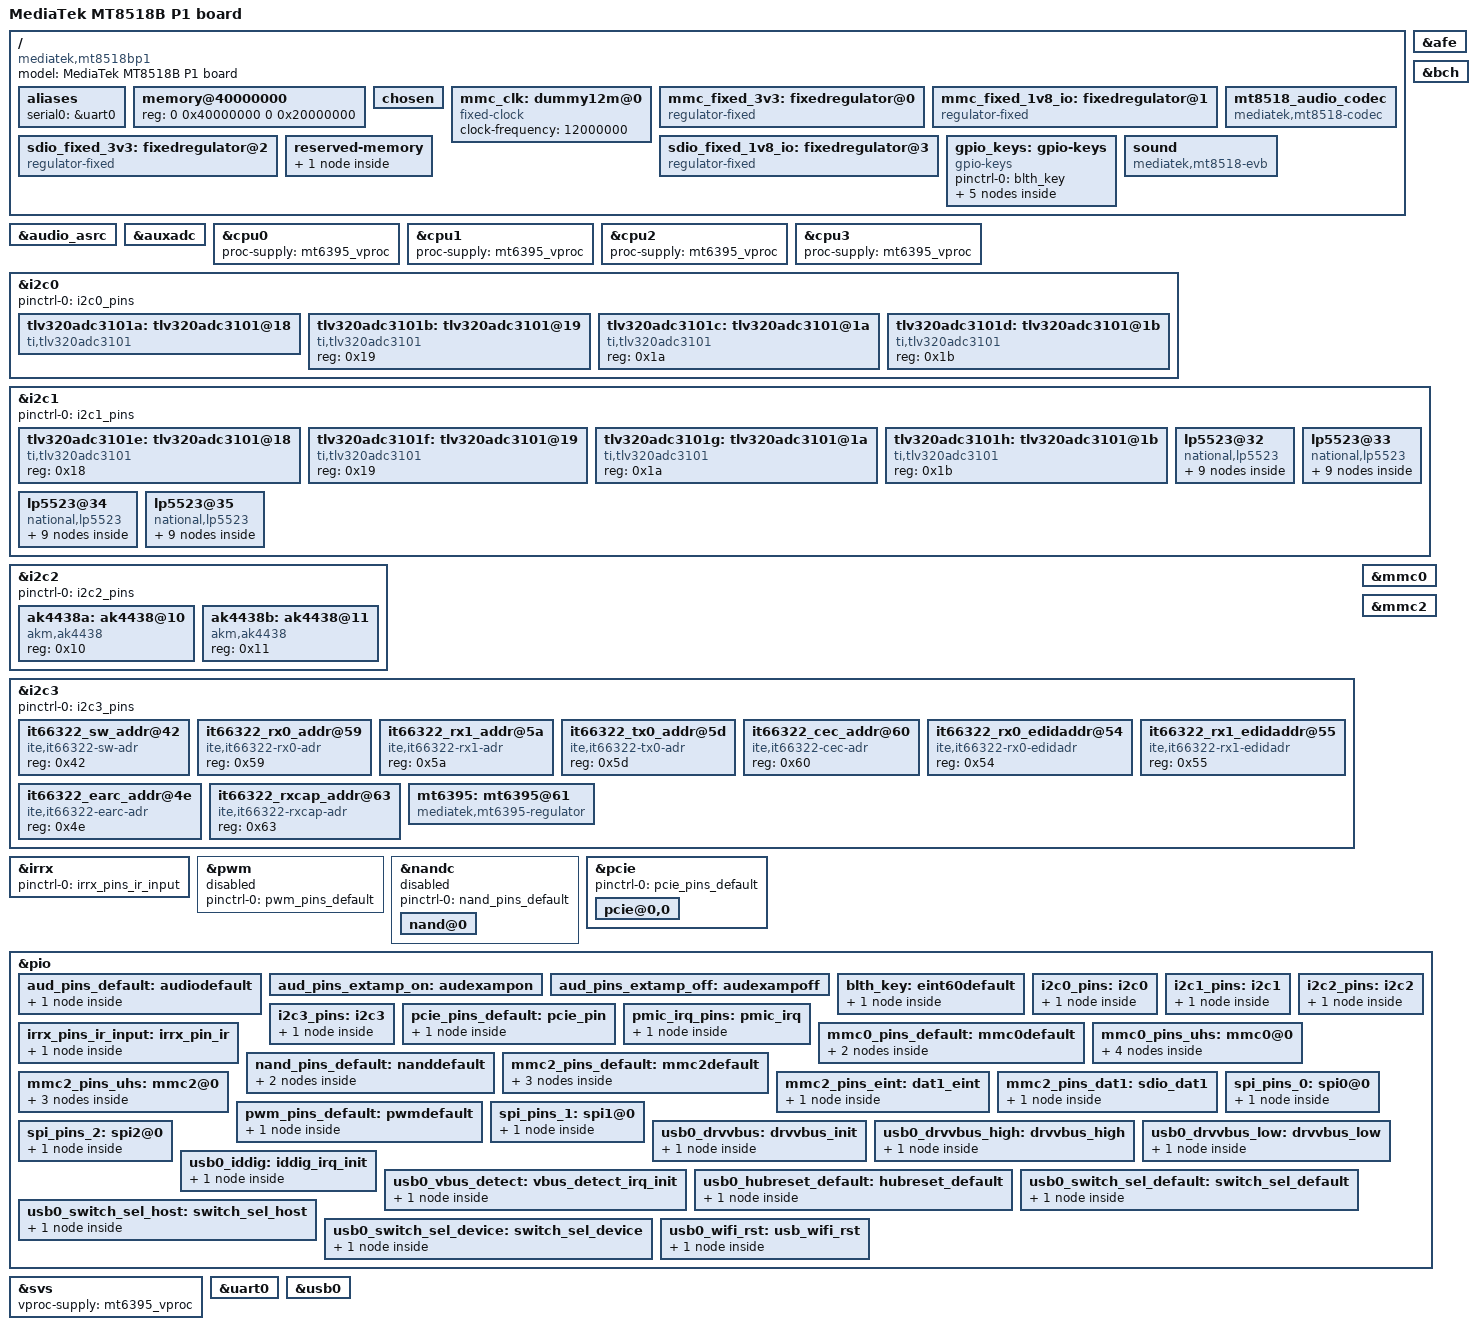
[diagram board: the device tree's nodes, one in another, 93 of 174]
/*
 * Copyright (c) 2018 MediaTek Inc.
 *
 * SPDX-License-Identifier: (GPL-2.0 OR MIT)
 */

/dts-v1/;
#include "mt8518b.dtsi"

/ {
	model = "MediaTek MT8518B P1 board";
	compatible = "mediatek,mt8518bp1", "mediatek,mt8518";

	aliases {
		serial0 = &uart0;
	};

	memory@40000000 {
		device_type = "memory";
		reg = <0 0x40000000 0 0x20000000>;
	};

	chosen {
		bootargs = "console=ttyS0,115200n1 root=/dev/mmcblk0p9 \
0x91ea22 earlycon=uart8250,mmio32,\
0x11005000 initcall_debug loglevel=8 \
androidboot.hardware=mt8518 \
firmware_class.path=/vendor/firmware";
	};

	mmc_clk: dummy12m@0 {
		compatible = "fixed-clock";
		clock-frequency = <12000000>;
		#clock-cells = <0>;
	};

	mmc_fixed_3v3: fixedregulator@0 {
		compatible = "regulator-fixed";
		regulator-name = "mmc_power";
		regulator-min-microvolt = <3300000>;
		regulator-max-microvolt = <3300000>;
		enable-active-high;
		regulator-always-on;
	};

	mmc_fixed_1v8_io: fixedregulator@1 {
		compatible = "regulator-fixed";
		regulator-name = "mmc_io";
		regulator-min-microvolt = <1800000>;
		regulator-max-microvolt = <1800000>;
		enable-active-high;
		regulator-always-on;
	};

	sdio_fixed_3v3: fixedregulator@2 {
			compatible = "regulator-fixed";
			regulator-name = "sdio_power";
			regulator-min-microvolt = <3300000>;
			regulator-max-microvolt = <3300000>;
			enable-active-high;
			regulator-always-on;
	};

	sdio_fixed_1v8_io: fixedregulator@3 {
			compatible = "regulator-fixed";
			regulator-name = "sdio_io";
			regulator-min-microvolt = <1800000>;
			regulator-max-microvolt = <1800000>;
			gpio = <&pio 55 0>;
			enable-active-high;
	};

	mt8518_audio_codec: mt8518_audio_codec {
		compatible = "mediatek,mt8518-codec";
		mediatek,afe-regmap = <&afe>;
		mediatek,apmixedsys-regmap = <&apmixedsys>;
		clocks = <&topckgen CLK_TOP_FAUD_INTBUS>;
		clock-names = "bus";
	};

	gpio_keys: gpio-keys {
		compatible = "gpio-keys";
		pinctrl-names = "default";
		pinctrl-0 = <&blth_key>;
		status = "okay";

		button@0 {
			debounce_interval = <50>;
			gpios = <&pio 57 1>;
			label = "volumeup";
			linux,input-type = <0x1>;
			linux,code = <115>;
		};

		button@1 {
			debounce_interval = <50>;
			gpios = <&pio 58 1>;
			label = "volumedown";
			linux,input-type = <0x1>;
			linux,code = <114>;
		};

		button@2 {
			debounce_interval = <50>;
			gpios = <&pio 61 1>;
			label = "bluetooth";
			linux,input-type = <0x1>;
			linux,code = <237>;
		};

		mute_button: button@3 {
			debounce_interval = <50>;
			gpios = <&pio 59 1>;
			label = "mute";
			linux,input-type = <0x1>;
			linux,code = <248>;
		};

		button@4 {
			debounce_interval = <50>;
			gpios = <&pio 62 1>;
			label = "switch";
			linux,input-type = <0x1>;
			linux,code = <31>;
		};

	};

	reserved-memory {
		mtee-reserved-memory {
			compatible = "mediatek,mt8518-mtee-reserved-memory";
			no-map;
			reg = <0 0x5FD00000 0 0x300000>;
		};
	};

	sound: sound {
		compatible = "mediatek,mt8518-evb";
		mediatek,platform = <&afe>;
		mediatek,etdm1-out-audio-codec-num = <2>;
		mediatek,etdm1-out-audio-codec0 = <&ak4438a>;
		mediatek,etdm1-out-audio-codec1 = <&ak4438b>;
		mediatek,etdm1-out-audio-codec0-prefix = "AK4438@10";
		mediatek,etdm1-out-audio-codec1-prefix = "AK4438@11";
		mediatek,etdm1-out-codec-dai-name0 = "ak4438-AIF";
		mediatek,etdm1-out-codec-dai-name1 = "ak4438-AIF";
		mediatek,etdm1-in-format = "dsp_a";
		mediatek,etdm1-in-lrck-width = <1>;
		mediatek,etdm1-in-audio-codec = <&tlv320adc3101a>;
		mediatek,etdm1-in-codec-dai-name = "tlv320adc3101-codec";
		mediatek,etdm1-in-fix-bit-width = <16>;
		mediatek,etdm1-in-fix-channels = <16>;
		mediatek,tlv320adc3101-codec-set-pll-clk-in-hw-params;
		mediatek,tlv320adc3101-codec-pll-id = <0>;
		mediatek,tlv320adc3101-codec-pll-src-id = <0>;
		mediatek,tlv320adc3101-codec-pll-clk-multiplier = <256>;
		mediatek,etdm2-in-format = "i2s";
		mediatek,etdm2-in-fix-bit-width = <32>;
		mediatek,int-adda-audio-codec=<&mt8518_audio_codec>;
		mediatek,int-adda-codec-dai-name="mt8518-codec-dai";
		mediatek,multi-in-fix-bit-width = <32>;
		pinctrl-names = "default", "extamp_on", "extamp_off";
		pinctrl-0 = <&aud_pins_default>;
		pinctrl-1 = <&aud_pins_extamp_on>;
		pinctrl-2 = <&aud_pins_extamp_off>;
		status = "okay";
	};
};

&afe {
	mediatek,dmic-iir-on;
	mediatek,etdm-clock-modes = <0 0>;
	mediatek,etdm-out-data-modes = <1 1>;
	mediatek,etdm-in-data-modes = <0 1>;
	mediatek,spdif-in-opt-mux = <0>;
	mediatek,spdif-in-arc-mux = <2>;
	mediatek,multi-in-clk-tuning-enabled;
	mediatek,multi-in-clk-tuning-period-ms = <1000>;
	mediatek,multi-in-clk-step-ppm = <1>;
	mediatek,multi-in-clk-step-interval-us = <200>;
	mediatek,spdif-in-clk-tuning-enabled;
	mediatek,spdif-in-clk-tuning-period-ms = <1000>;
	mediatek,spdif-in-clk-step-ppm = <1>;
	mediatek,spdif-in-clk-step-interval-us = <200>;
	mediatek,etdm1-out-clk-tuning-enabled;
	status = "okay";
};

&audio_asrc {
	status = "okay";
};

&auxadc {
	status = "okay";
};

&bch {
	status = "okay";
};

&cpu0 {
	proc-supply = <&mt6395_vproc>;
};

&cpu1 {
	proc-supply = <&mt6395_vproc>;
};

&cpu2 {
	proc-supply = <&mt6395_vproc>;
};

&cpu3 {
	proc-supply = <&mt6395_vproc>;
};

&i2c0 {
	pinctrl-names = "default";
	pinctrl-0 = <&i2c0_pins>;
	status = "okay";

	tlv320adc3101a: tlv320adc3101@18 {
		compatible = "ti,tlv320adc3101";
		reg = <0x18>;
		rst-gpio = <&pio 19 0>;
		adc-pos = <0>;
		dmic-en =<0>;
		diff-single = <0>;
		left-adc-sel = <2>;
		right-adc-sel = <2>;
	};

	tlv320adc3101b: tlv320adc3101@19 {
		compatible = "ti,tlv320adc3101";
		reg = <0x19>;
	};

	tlv320adc3101c: tlv320adc3101@1a {
		compatible = "ti,tlv320adc3101";
		reg = <0x1a>;
	};

	tlv320adc3101d: tlv320adc3101@1b {
		compatible = "ti,tlv320adc3101";
		reg = <0x1b>;
	};

};

&i2c1 {
	pinctrl-names = "default";
	pinctrl-0 = <&i2c1_pins>;
	status = "okay";

	tlv320adc3101e: tlv320adc3101@18 {
		compatible = "ti,tlv320adc3101";
		reg = <0x18>;
	};

	tlv320adc3101f: tlv320adc3101@19 {
		compatible = "ti,tlv320adc3101";
		reg = <0x19>;
	};

	tlv320adc3101g: tlv320adc3101@1a {
		compatible = "ti,tlv320adc3101";
		reg = <0x1a>;
	};

	tlv320adc3101h: tlv320adc3101@1b {
		compatible = "ti,tlv320adc3101";
		reg = <0x1b>;
	};

	lp5523@32{
	compatible = "national,lp5523";
	reg = <0x32>;
	enable-gpio = <&pio 25 0>;
	clock-mode = /bits/ 8 <1>;

	chan0 {
		chan-name = "d1";
		led-cur = /bits/ 8 <0x20>;
		max-cur = /bits/ 8 <0xff>;
	};

	chan1 {
		chan-name = "d2";
		led-cur = /bits/ 8 <0x20>;
		max-cur = /bits/ 8 <0xff>;
	};

	chan2 {
		chan-name = "d3";
		led-cur = /bits/ 8 <0x20>;
		max-cur = /bits/ 8 <0xff>;
	};

	chan3 {
		chan-name = "d4";
		led-cur = /bits/ 8 <0x20>;
		max-cur = /bits/ 8 <0xff>;
	};

	chan4 {
		chan-name = "d5";
		led-cur = /bits/ 8 <0x20>;
		max-cur = /bits/ 8 <0xff>;
	};

	chan5 {
		chan-name = "d6";
		led-cur = /bits/ 8 <0x20>;
		max-cur = /bits/ 8 <0xff>;
	};

	chan6 {
		chan-name = "d7";
		led-cur = /bits/ 8 <0x20>;
		max-cur = /bits/ 8 <0xff>;
	};

	chan7 {
		chan-name = "d8";
		led-cur = /bits/ 8 <0x20>;
		max-cur = /bits/ 8 <0xff>;
	};

	chan8 {
		chan-name = "d9";
		led-cur = /bits/ 8 <0x20>;
		max-cur = /bits/ 8 <0xff>;
		};
	};
	lp5523@33{
	compatible = "national,lp5523";
	reg = <0x33>;
	enable-gpio = <&pio 25 0>;
	clock-mode = /bits/ 8 <1>;

	chan0 {
		chan-name = "d1_1";
		led-cur = /bits/ 8 <0x20>;
		max-cur = /bits/ 8 <0xff>;
	};

	chan1 {
		chan-name = "d1_2";
		led-cur = /bits/ 8 <0x20>;
		max-cur = /bits/ 8 <0xff>;
	};

	chan2 {
		chan-name = "d1_3";
		led-cur = /bits/ 8 <0x20>;
		max-cur = /bits/ 8 <0xff>;
	};
	chan3 {
		chan-name = "d1_4";
		led-cur = /bits/ 8 <0x20>;
		max-cur = /bits/ 8 <0xff>;
	};

	chan4 {
		chan-name = "d1_5";
		led-cur = /bits/ 8 <0x20>;
		max-cur = /bits/ 8 <0xff>;
	};

	chan5 {
		chan-name = "d1_6";
		led-cur = /bits/ 8 <0x20>;
		max-cur = /bits/ 8 <0xff>;
	};

	chan6 {
		chan-name = "d1_7";
		led-cur = /bits/ 8 <0x20>;
		max-cur = /bits/ 8 <0xff>;
	};

	chan7 {
		chan-name = "d1_8";
		led-cur = /bits/ 8 <0x20>;
		max-cur = /bits/ 8 <0xff>;
	};

	chan8 {
		chan-name = "d1_9";
		led-cur = /bits/ 8 <0x20>;
		max-cur = /bits/ 8 <0xff>;
		};
	};
	lp5523@34{
	compatible = "national,lp5523";
	reg = <0x34>;
	enable-gpio = <&pio 25 0>;
	clock-mode = /bits/ 8 <1>;

	chan0 {
		chan-name = "d2_1";
		led-cur = /bits/ 8 <0x20>;
		max-cur = /bits/ 8 <0xff>;
	};

	chan1 {
		chan-name = "d2_2";
		led-cur = /bits/ 8 <0x20>;
		max-cur = /bits/ 8 <0xff>;
	};

	chan2 {
		chan-name = "d2_3";
		led-cur = /bits/ 8 <0x20>;
		max-cur = /bits/ 8 <0xff>;
	};

	chan3 {
		chan-name = "d2_4";
		led-cur = /bits/ 8 <0x20>;
		max-cur = /bits/ 8 <0xff>;
	};

	chan4 {
		chan-name = "d2_5";
		led-cur = /bits/ 8 <0x20>;
		max-cur = /bits/ 8 <0xff>;
	};

	chan5 {
		chan-name = "d2_6";
		led-cur = /bits/ 8 <0x20>;
		max-cur = /bits/ 8 <0xff>;
	};

	chan6 {
		chan-name = "d2_7";
		led-cur = /bits/ 8 <0x20>;
		max-cur = /bits/ 8 <0xff>;
	};

	chan7 {
		chan-name = "d2_8";
		led-cur = /bits/ 8 <0x20>;
		max-cur = /bits/ 8 <0xff>;
	};

	chan8 {
		chan-name = "d2_9";
		led-cur = /bits/ 8 <0x20>;
		max-cur = /bits/ 8 <0xff>;
		};
	};
	lp5523@35{
	compatible = "national,lp5523";
	reg = <0x35>;
	enable-gpio = <&pio 25 0>;
	clock-mode = /bits/ 8 <1>;

	chan0 {
		chan-name = "d3_1";
		led-cur = /bits/ 8 <0x20>;
		max-cur = /bits/ 8 <0xff>;
	};

	chan1 {
		chan-name = "d3_2";
		led-cur = /bits/ 8 <0x20>;
		max-cur = /bits/ 8 <0xff>;
	};

	chan2 {
		chan-name = "d3_3";
		led-cur = /bits/ 8 <0x20>;
		max-cur = /bits/ 8 <0xff>;
	};

	chan3 {
		chan-name = "d3_4";
		led-cur = /bits/ 8 <0x20>;
		max-cur = /bits/ 8 <0xff>;
	};

	chan4 {
		chan-name = "d3_5";
		led-cur = /bits/ 8 <0x20>;
		max-cur = /bits/ 8 <0xff>;
	};

	chan5 {
		chan-name = "d3_6";
		led-cur = /bits/ 8 <0x20>;
		max-cur = /bits/ 8 <0xff>;
	};

	chan6 {
		chan-name = "d3_7";
		led-cur = /bits/ 8 <0x20>;
		max-cur = /bits/ 8 <0xff>;
	};

	chan7 {
		chan-name = "d3_8";
		led-cur = /bits/ 8 <0x20>;
		max-cur = /bits/ 8 <0xff>;
	};

	chan8 {
		chan-name = "d3_9";
		led-cur = /bits/ 8 <0x20>;
		max-cur = /bits/ 8 <0xff>;
		};
	};
};

&i2c2 {
	pinctrl-names = "default";
	pinctrl-0 = <&i2c2_pins>;
	status = "okay";

	ak4438a: ak4438@10 {
		compatible = "akm,ak4438";
		reg = <0x10>;
	};

	ak4438b: ak4438@11 {
		compatible = "akm,ak4438";
		reg = <0x11>;
	};
};

&i2c3 {
	pinctrl-names = "default";
	pinctrl-0 = <&i2c3_pins>;
	status = "okay";

#if 0
	/*for it6620*/
	it66121_addr@4c {
		compatible = "ite,it66121-i2c";
		reg = <0x4c>;
	};
	it6620_basic_addr@4e {
		compatible = "ite,it6620-basic-i2c";
		reg = <0x4e>;
	};
	it6620_cec_addr@65 {
		compatible = "ite,it6620-cec-i2c";
		reg = <0x65>;
	};
	it6620_cap_addr@63 {
		compatible = "ite,it6620-cap-i2c";
		reg = <0x63>;
	};
#else
	/*for it66322*/
	it66322_sw_addr@42 {
		compatible = "ite,it66322-sw-adr";
		reg = <0x42>;
	};
	it66322_rx0_addr@59 {
		compatible = "ite,it66322-rx0-adr";
		reg = <0x59>;
	};
	it66322_rx1_addr@5a {
		compatible = "ite,it66322-rx1-adr";
		reg = <0x5a>;
	};
	it66322_tx0_addr@5d {
		compatible = "ite,it66322-tx0-adr";
		reg = <0x5d>;
	};
	it66322_cec_addr@60 {
		compatible = "ite,it66322-cec-adr";
		reg = <0x60>;
	};
	it66322_rx0_edidaddr@54 {
		compatible = "ite,it66322-rx0-edidadr";
		reg = <0x54>;
	};
	it66322_rx1_edidaddr@55 {
		compatible = "ite,it66322-rx1-edidadr";
		reg = <0x55>;
	};
	it66322_earc_addr@4e {
		compatible = "ite,it66322-earc-adr";
		reg = <0x4e>;
	};
	it66322_rxcap_addr@63 {
		compatible = "ite,it66322-rxcap-adr";
		reg = <0x63>;
	};
#endif

	mt6395: mt6395@61 {
		compatible = "mediatek,mt6395-regulator";
		pinctrl-names = "default";
		pinctrl-0 = <&pmic_irq_pins>;
		mt6395,irq-gpios = <&pio 27 0x0>;
		reg = <0x61>;
		status = "okay";
	};
};

&irrx {
	pinctrl-names = "default";
	pinctrl-0 = <&irrx_pins_ir_input>;
	status = "okay";
};

&pwm {
	pinctrl-names = "default";
	pinctrl-0 = <&pwm_pins_default>;
	status = "disabled";
};

&mmc0 {
	pinctrl-names = "default", "state_uhs";
	pinctrl-0 = <&mmc0_pins_default>;
	pinctrl-1 = <&mmc0_pins_uhs>;
	status = "okay";
	bus-width = <8>;
	max-frequency = <200000000>;
	cap-mmc-highspeed;
	cap-mmc-hw-reset;
	mmc-hs200-1_8v;
	mmc-hs400-1_8v;
	hs400-ds-delay = <0x1201d>;
	r_smpl = <0>;
	vmmc-supply = <&mmc_fixed_3v3>;
	vqmmc-supply = <&mmc_fixed_1v8_io>;
	no-sdio;
	no-sd;
	non-removable;
};

&mmc2 {
	status = "okay";
	pinctrl-names = "default", "state_uhs", "state_eint", "state_dat1";
	pinctrl-0 = <&mmc2_pins_default>;
	pinctrl-1 = <&mmc2_pins_uhs>;
	pinctrl-2 = <&mmc2_pins_eint>;
	pinctrl-3 = <&mmc2_pins_dat1>;
	eint-gpios = <&pio 32 0>;
	bus-width = <4>;
	max-frequency = <200000000>;
	cap-sd-highspeed;
	/*sd-uhs-ddr208;*/
	drv-type = <2>;
	sd-uhs-sdr104;
	sd-uhs-sdr50;
	keep-power-in-suspend;
	enable-sdio-wakeup;
	cap-sdio-irq;
	hs400-ds-delay = <0x1401B>;
	no-sd;
	no-mmc;
	non-removable;
	vmmc-supply = <&sdio_fixed_3v3>;
	vqmmc-supply = <&sdio_fixed_1v8_io>;
};

&nandc {
	pinctrl-names = "default";
	pinctrl-0 = <&nand_pins_default>;
	status = "disabled";
	nand@0 {
		reg = <0>;
		nand-on-flash-bbt;
		nand-ecc-mode = "hw";
	};
};

&pcie {
	pinctrl-names = "default";
	pinctrl-0 = <&pcie_pins_default>;
	pcie@0,0 {
		speed =  <1>;
		rst-gpio = <&pio 116 0>;
		rst-2g-gpio = <&pio 114 0>;
		rst-5g-gpio = <&pio 115 0>;
		status = "okay";
	};
};

&pio {
	pinctrl-names = "default";

	aud_pins_default: audiodefault {
		pins_cmd_dat {
			pinmux = <MT8518_PIN_47_EINT11__FUNC_SPLIN_BCK>,
				<MT8518_PIN_48_EINT12__FUNC_SPLIN_LRCK>,
				<MT8518_PIN_49_EINT13__FUNC_SPLIN_D0>,
				<MT8518_PIN_50_EINT14__FUNC_SPLIN_D1>,
				<MT8518_PIN_51_EINT15__FUNC_SPLIN_D2>,
				<MT8518_PIN_63_I2SO_MCLK__FUNC_TDMO_MCLK>,
				<MT8518_PIN_64_I2SO_BCK__FUNC_TDMO_BCK>,
				<MT8518_PIN_65_I2SO_LRCK__FUNC_TDMO_LRCK>,
				<MT8518_PIN_66_I2SO_D0__FUNC_TDMO_DO>,
				<MT8518_PIN_67_I2SO_D1__FUNC_TDMO_DO1>,
				<MT8518_PIN_68_I2SO_D2__FUNC_TDMO_DO2>,
				<MT8518_PIN_69_I2SO_D3__FUNC_TDMO_DO3>,
				<MT8518_PIN_70_SPDIF_IN0__FUNC_SPDIF_IN_0>,
				<MT8518_PIN_71_DMIC_CLK0__FUNC_DMIC_CLK0>,
				<MT8518_PIN_72_DMIC_CLK1__FUNC_DMIC_CLK1>,
				<MT8518_PIN_73_DMIC_DAT0__FUNC_DMIC_DAT0>,
				<MT8518_PIN_74_DMIC_DAT1__FUNC_DMIC_DAT1>,
				<MT8518_PIN_75_DMIC_DAT2__FUNC_DMIC_DAT2>,
				<MT8518_PIN_76_DMIC_DAT3__FUNC_DMIC_DAT3>,
				<MT8518_PIN_77_TDM_MCLK__FUNC_TDMIN_MCLK>,
				<MT8518_PIN_78_TDM_BCK__FUNC_TDMIN_BCK>,
				<MT8518_PIN_79_TDM_LRCK__FUNC_TDMIN_LRCK>,
				<MT8518_PIN_80_TDM_DI__FUNC_TDMIN_DI>,
				<MT8518_PIN_81_I2SIN_D0__FUNC_I2SIN_D0>,
				<MT8518_PIN_84_I2SIN_D3__FUNC_SPLIN_D3>,
				<MT8518_PIN_85_I2SIN_MCLK__FUNC_I2SIN_MCLKA>,
				<MT8518_PIN_86_I2SIN_BCK__FUNC_I2SIN_BCKA>,
				<MT8518_PIN_87_I2SIN_LRCK__FUNC_I2SIN_LRCKA>,
				<MT8518_PIN_92_SPI2_CS__FUNC_TDMO_DO4>,
				<MT8518_PIN_93_SPI2_CK__FUNC_TDMO_DO5>,
				<MT8518_PIN_94_SPI2_MI0__FUNC_TDMO_DO6>,
				<MT8518_PIN_95_SPI2_MI1__FUNC_TDMO_DO7>,
				<MT8518_PIN_103_RTC32K_DSP__FUNC_SPDIF_IN_2>;
		};
	};

	aud_pins_extamp_on: audexampon {
	};

	aud_pins_extamp_off: audexampoff {
	};

	blth_key: eint60default {
		pins_cmd_dat {
			pinmux = <MT8518_PIN_57_EINT16__FUNC_GPIO57>,
				<MT8518_PIN_58_EINT17__FUNC_GPIO58>,
				<MT8518_PIN_59_EINT18__FUNC_GPIO59>,
				<MT8518_PIN_61_EINT20__FUNC_GPIO61>,
				<MT8518_PIN_62_EINT21__FUNC_GPIO62>;
			slew-rate = <0>;
			bias-pull-up = <MTK_PUPD_SET_R1R0_01>;
			input-enable;
		};
	};

	i2c0_pins: i2c0 {
		pins_bus {
			pinmux = <MT8518_PIN_110_SDA0__FUNC_SDA0_0>,
				 <MT8518_PIN_111_SCL0__FUNC_SCL0_0>;
			bias-disable;
		};
	};

	i2c1_pins: i2c1 {
		pins_bus {
			pinmux = <MT8518_PIN_108_SDA1__FUNC_SDA1_0>,
				 <MT8518_PIN_109_SCL1__FUNC_SCL1_0>;
			bias-disable;
		};
	};

	i2c2_pins: i2c2 {
		pins_bus {
			pinmux = <MT8518_PIN_112_SDA2__FUNC_SDA2_0>,
				 <MT8518_PIN_113_SCL2__FUNC_SCL2_0>;
			bias-disable;
		};
	};

	i2c3_pins: i2c3 {
		pins_bus {
			pinmux = <MT8518_PIN_21_SDA3__FUNC_SDA3_0>,
				 <MT8518_PIN_22_SCL3__FUNC_SCL3_0>;
			bias-disable;
		};
	};

	pcie_pins_default: pcie_pin {
		pins_pcie {
			pinmux = <MT8518_PIN_116_MSDC1_DAT0__FUNC_GPIO116>,
				<MT8518_PIN_119_MSDC1_DAT3__FUNC_GPIO119>,
				<MT8518_PIN_60_EINT19__FUNC_PCIE_CLKREQ>;
			bias-disable;
		};
	};

	irrx_pins_ir_input: irrx_pin_ir {
		pins_cmd_dat {
			pinmux = <MT8518_PIN_56_IR__FUNC_IR>;
			bias-disable;
		};
	};

	pmic_irq_pins: pmic_irq {
		pins_bus {
			pinmux = <MT8518_PIN_27_PWRAP_INT__FUNC_GPIO27>;
			bias-pull-up = <MTK_PUPD_SET_R1R0_01>;
		};
	};

	mmc0_pins_default: mmc0default {
		pins_cmd_dat {
			pinmux = <MT8518_PIN_13_MSDC0_DAT0__FUNC_MSDC0_DAT0>,
				<MT8518_PIN_12_MSDC0_DAT1__FUNC_MSDC0_DAT1>,
				<MT8518_PIN_11_MSDC0_DAT2__FUNC_MSDC0_DAT2>,
				<MT8518_PIN_10_MSDC0_DAT3__FUNC_MSDC0_DAT3>,
				<MT8518_PIN_6_MSDC0_DAT4__FUNC_MSDC0_DAT4>,
				<MT8518_PIN_5_MSDC0_DAT5__FUNC_MSDC0_DAT5>,
				<MT8518_PIN_4_MSDC0_DAT6__FUNC_MSDC0_DAT6>,
				<MT8518_PIN_3_MSDC0_DAT7__FUNC_MSDC0_DAT7>,
				<MT8518_PIN_8_MSDC0_CMD__FUNC_MSDC0_CMD>;
			input-enable;
			bias-pull-up;
		};

		pins_clk {
			pinmux = <MT8518_PIN_9_MSDC0_CLK__FUNC_MSDC0_CLK>;
			bias-pull-down;
		};
	};

	mmc0_pins_uhs: mmc0@0{
		pins_cmd_dat {
			pinmux = <MT8518_PIN_13_MSDC0_DAT0__FUNC_MSDC0_DAT0>,
				 <MT8518_PIN_12_MSDC0_DAT1__FUNC_MSDC0_DAT1>,
				 <MT8518_PIN_11_MSDC0_DAT2__FUNC_MSDC0_DAT2>,
				 <MT8518_PIN_10_MSDC0_DAT3__FUNC_MSDC0_DAT3>,
				 <MT8518_PIN_6_MSDC0_DAT4__FUNC_MSDC0_DAT4>,
				 <MT8518_PIN_5_MSDC0_DAT5__FUNC_MSDC0_DAT5>,
				 <MT8518_PIN_4_MSDC0_DAT6__FUNC_MSDC0_DAT6>,
				 <MT8518_PIN_3_MSDC0_DAT7__FUNC_MSDC0_DAT7>,
				 <MT8518_PIN_8_MSDC0_CMD__FUNC_MSDC0_CMD>;
			input-enable;
			drive-strength = <MTK_DRIVE_6mA>;
			bias-pull-up;
		};

		pins_clk {
			pinmux = <MT8518_PIN_9_MSDC0_CLK__FUNC_MSDC0_CLK>;
			drive-strength = <MTK_DRIVE_8mA>;
			bias-pull-down;
		};

		pins_ds {
			pinmux = <MT8518_PIN_2_NFI_NRNB__FUNC_MSDC0_DS>;
			bias-pull-down = <MTK_PUPD_SET_R1R0_10>;
		};

		pins_rst {
			pinmux = <MT8518_PIN_7_MSDC0_RSTB__FUNC_MSDC0_RSTB>;
			bias-pull-up;
		};
	};

	nand_pins_default: nanddefault {
		pins_dat {
			pinmux = <MT8518_PIN_3_MSDC0_DAT7__FUNC_NLD7>,
				 <MT8518_PIN_4_MSDC0_DAT6__FUNC_NLD6>,
				 <MT8518_PIN_5_MSDC0_DAT5__FUNC_NLD4>,
				 <MT8518_PIN_6_MSDC0_DAT4__FUNC_NLD3>,
				 <MT8518_PIN_7_MSDC0_RSTB__FUNC_NLD0>,
				 <MT8518_PIN_10_MSDC0_DAT3__FUNC_NLD1>,
				 <MT8518_PIN_11_MSDC0_DAT2__FUNC_NLD5>,
				 <MT8518_PIN_13_MSDC0_DAT0__FUNC_NLD2>;
			input-enable;
			bias-pull-up;
		};

		pins_cmd {
			pinmux = <MT8518_PIN_0_NFI_NCEB0__FUNC_NCEB0>,
				 <MT8518_PIN_1_NFI_NREB__FUNC_NREB>,
				 <MT8518_PIN_2_NFI_NRNB__FUNC_NRNB>,
				 <MT8518_PIN_8_MSDC0_CMD__FUNC_NALE>,
				 <MT8518_PIN_9_MSDC0_CLK__FUNC_NWEB>,
				 <MT8518_PIN_12_MSDC0_DAT1__FUNC_NCLE>;
			bias-pull-up;
		};
	};

	mmc2_pins_default: mmc2default {
		pins_cmd_dat {
			pinmux = <MT8518_PIN_29_MSDC2_CMD__FUNC_MSDC2_CMD>,
			       <MT8518_PIN_31_MSDC2_DAT0__FUNC_MSDC2_DAT0>,
			       <MT8518_PIN_32_MSDC2_DAT1__FUNC_MSDC2_DAT1>,
			       <MT8518_PIN_33_MSDC2_DAT2__FUNC_MSDC2_DAT2>,
			       <MT8518_PIN_34_MSDC2_DAT3__FUNC_MSDC2_DAT3>;
			input-enable;
			bias-pull-up = <MTK_PUPD_SET_R1R0_01>;
		};

		pins_clk {
			pinmux = <MT8518_PIN_30_MSDC2_CLK__FUNC_MSDC2_CLK>;
			bias-pull-down = <MTK_PUPD_SET_R1R0_10>;
		};

		pins_wifi_clk {
			pinmux = <MT8518_PIN_23_PWRAP_SPI_CLK__FUNC_GPIO23>,
			       <MT8518_PIN_54_URTS1__FUNC_GPIO54>;
			input-enable;
			bias-disable;
		};
	};

	mmc2_pins_uhs: mmc2@0{
		pins_cmd_dat {
			pinmux = <MT8518_PIN_29_MSDC2_CMD__FUNC_MSDC2_CMD>,
			       <MT8518_PIN_31_MSDC2_DAT0__FUNC_MSDC2_DAT0>,
			       <MT8518_PIN_32_MSDC2_DAT1__FUNC_MSDC2_DAT1>,
			       <MT8518_PIN_33_MSDC2_DAT2__FUNC_MSDC2_DAT2>,
			       <MT8518_PIN_34_MSDC2_DAT3__FUNC_MSDC2_DAT3>;
			input-enable;
			drive-strength = <MTK_DRIVE_4mA>;
			bias-pull-up = <MTK_PUPD_SET_R1R0_01>;
		};

		pins_clk {
			pinmux = <MT8518_PIN_30_MSDC2_CLK__FUNC_MSDC2_CLK>;
			drive-strength = <MTK_DRIVE_4mA>;
			bias-pull-down = <MTK_PUPD_SET_R1R0_10>;
		};

		pins_ds {
			pinmux = <MT8518_PIN_35_MSDC2_DS__FUNC_MSDC2_DS>;
			drive-strength = <MTK_DRIVE_4mA>;
			bias-pull-down = <MTK_PUPD_SET_R1R0_10>;
		};
	};

	mmc2_pins_eint: dat1_eint {
		pins_dat1 {
			pinmux = <MT8518_PIN_32_MSDC2_DAT1__FUNC_GPIO32>;
			output-high;
		};
	};

	mmc2_pins_dat1: sdio_dat1 {
		pins_dat1 {
			pinmux = <MT8518_PIN_32_MSDC2_DAT1__FUNC_MSDC2_DAT1>;
			input-enable;
			drive-strength = <MTK_DRIVE_4mA>;
			bias-pull-up = <MTK_PUPD_SET_R1R0_01>;
		};
	};

	pwm_pins_default: pwmdefault {
		pins_cmd_dat {
			pinmux = <MT8518_PIN_88_SPI1_CS__FUNC_PWM_A>,
				 <MT8518_PIN_89_SPI1_CK__FUNC_PWM_B>,
				 <MT8518_PIN_90_SPI1_MI__FUNC_PWM_C>;
		};
	};

	spi_pins_0: spi0@0 {
		pins_spi {
			pinmux = <MT8518_PIN_29_MSDC2_CMD__FUNC_SPI0_CSB>,
				<MT8518_PIN_30_MSDC2_CLK__FUNC_SPI0_CLK>,
				<MT8518_PIN_31_MSDC2_DAT0__FUNC_SPI0_MI>,
				<MT8518_PIN_32_MSDC2_DAT1__FUNC_SPI0_MO>;
			bias-disable;
			};
	};

	spi_pins_1: spi1@0 {
		pins_spi {
			pinmux = <MT8518_PIN_92_SPI2_CS__FUNC_SPI2_CSB>,
				<MT8518_PIN_93_SPI2_CK__FUNC_SPI2_CLK>,
				<MT8518_PIN_94_SPI2_MI0__FUNC_SPI2_MI0>,
				<MT8518_PIN_95_SPI2_MI1__FUNC_SPI2_MI1>,
				<MT8518_PIN_96_SPI2_MI2__FUNC_SPI2_MI2>,
				<MT8518_PIN_97_SPI2_MI3__FUNC_SPI2_MI3>;
			bias-disable;
		};
	};

	spi_pins_2: spi2@0 {
		pins_spi {
			pinmux = <MT8518_PIN_88_SPI1_CS__FUNC_SPI1_CSB>,
				<MT8518_PIN_89_SPI1_CK__FUNC_SPI1_CLK>,
				<MT8518_PIN_90_SPI1_MI__FUNC_SPI1_MI>,
				<MT8518_PIN_91_SPI1_MO__FUNC_SPI1_MO>;
			bias-disable;
		};
	};

	/* USB GPIO start */
	usb0_drvvbus: drvvbus_init {
		pins_cmd_dat {
			pinmux = <MT8518_PIN_57_EINT16__FUNC_GPIO57>;
			output-low;
		};
	};

	usb0_drvvbus_high: drvvbus_high {
		pins_cmd_dat {
			pinmux = <MT8518_PIN_57_EINT16__FUNC_GPIO57>;
			output-high;
		};
	};

	usb0_drvvbus_low: drvvbus_low {
		pins_cmd_dat {
			pinmux = <MT8518_PIN_57_EINT16__FUNC_GPIO57>;
			output-low;
		};
	};

	usb0_iddig: iddig_irq_init {
		pins_cmd_dat {
			pinmux = <MT8518_PIN_118_MSDC1_DAT2__FUNC_GPIO118>;
			bias-pull-up;
		};
	};

	usb0_vbus_detect: vbus_detect_irq_init {
		pins_cmd_dat {
			pinmux = <MT8518_PIN_60_EINT19__FUNC_GPIO60>;
			bias-disable;
		};
	};

	usb0_hubreset_default: hubreset_default {
		pins_cmd_dat {
			pinmux = <MT8518_PIN_91_SPI1_MO__FUNC_GPIO91>;
			output-high;
		};
	};

	usb0_switch_sel_default: switch_sel_default {
		pins_cmd_dat {
			pinmux = <MT8518_PIN_117_MSDC1_DAT1__FUNC_GPIO117>;
			output-low;
		};
	};

	usb0_switch_sel_host: switch_sel_host {
		pins_cmd_dat {
			pinmux = <MT8518_PIN_117_MSDC1_DAT1__FUNC_GPIO117>;
			output-low;
		};
	};

	usb0_switch_sel_device: switch_sel_device {
		pins_cmd_dat {
			pinmux = <MT8518_PIN_117_MSDC1_DAT1__FUNC_GPIO117>;
			output-high;
		};
	};

	usb0_wifi_rst: usb_wifi_rst {
		pins_cmd_dat {
			pinmux = <MT8518_PIN_115_MSDC1_CLK__FUNC_GPIO115>;
			output-low;
		};
	};
	/* USB GPIO end */
};

&svs {
	vproc-supply = <&mt6395_vproc>;
};

&uart0 {
	status = "okay";
};

&usb0 {
	interrupts-extended = <&sysirq GIC_SPI 72 IRQ_TYPE_LEVEL_LOW>;
	pinctrl-names = "iddig_irq_init",
			"drvvbus_init",
			"drvvbus_low",
			"drvvbus_high",
			"vbus_detect_irq_init",
			"hubreset_default",
			"switch_sel_default",
			"switch_sel_host",
			"switch_sel_device",
			"wifi_rst";
	pinctrl-0 = <&usb0_iddig>;
	pinctrl-1 = <&usb0_drvvbus>;
	pinctrl-2 = <&usb0_drvvbus_low>;
	pinctrl-3 = <&usb0_drvvbus_high>;
	pinctrl-4 = <&usb0_vbus_detect>;
	pinctrl-5 = <&usb0_hubreset_default>;
	pinctrl-6 = <&usb0_switch_sel_default>;
	pinctrl-7 = <&usb0_switch_sel_host>;
	pinctrl-8 = <&usb0_switch_sel_device>;
	status = "okay";
	sw_default_mode = <2>;
	hubreset_exist = <1>;
	switchsel_exist = <1>;
	iddig_gpio = <&pio 118 0>;
	drvvbus_gpio = <&pio 57 0>;
	vbusdetect_gpio = <&pio 60 0>;
	hubreset_gpio = <&pio 91 0>;
	switchsel_gpio = <&pio 117 0>;
};

#include "mt6395.dtsi"
